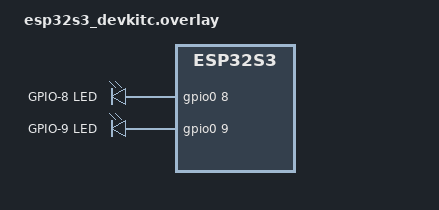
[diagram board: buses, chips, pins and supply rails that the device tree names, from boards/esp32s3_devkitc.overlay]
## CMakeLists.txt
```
cmake_minimum_required(VERSION 3.20.0)

find_package(Zephyr REQUIRED HINTS $ENV{ZEPHYR_BASE})
project(multi_thread_blinky LANGUAGES C)

target_sources(app PRIVATE src/main.c)
```

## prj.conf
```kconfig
# esp32s3_demo/prj.conf
CONFIG_ESPTOOLPY_FLASHSIZE_16MB=y
CONFIG_GPIO=y
CONFIG_LOG=y
CONFIG_LOG_DEFAULT_LEVEL=3
CONFIG_MAIN_STACK_SIZE=4096

# Use minimal C library to avoid picolibc/newlib complications
CONFIG_MINIMAL_LIBC=y
CONFIG_PICOLIBC=n
CONFIG_NEWLIB_LIBC=n

# Comms

CONFIG_CONSOLE=y
CONFIG_UART_CONSOLE=y
CONFIG_SERIAL=y
CONFIG_STDOUT_CONSOLE=y

# For debug
CONFIG_DEBUG=y
CONFIG_DEBUG_THREAD_INFO=y
CONFIG_ASSERT=y

# Thread Analyzer (diagnostic - off by default). Uncomment all three to print
# per-thread stack high-water marks to the console every 10 s; useful for
# checking stack headroom or right-sizing stacks. THREAD_ANALYZER auto-selects
# INIT_STACKS so the figures are accurate. Leave commented for normal runs.
# CONFIG_THREAD_ANALYZER=y
# CONFIG_THREAD_ANALYZER_AUTO=y
# CONFIG_THREAD_ANALYZER_AUTO_INTERVAL=10
```

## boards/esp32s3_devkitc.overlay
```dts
/ {
    aliases {
        led0 = &onboard_led;
        led1 = &second_led;
    };

    leds {
        compatible = "gpio-leds";

        onboard_led: led_0 {
            gpios = <&gpio0 8 GPIO_ACTIVE_HIGH>;
            label = "GPIO-8 LED";
        };

        second_led: led_1 {
            gpios = <&gpio0 9 GPIO_ACTIVE_HIGH>;
            label = "GPIO-9 LED";
        };
    };
};

&flash0 {
	reg = <0x0 DT_SIZE_M(16)>;
};
```

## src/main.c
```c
/*
 * Copyright (c) 2025 John O'Sullivan
 *
 * SPDX-License-Identifier: Apache-2.0
 */

#include <zephyr/kernel.h>
#include <zephyr/drivers/gpio.h>
#include <zephyr/logging/log.h>

LOG_MODULE_REGISTER(mtblink, LOG_LEVEL_INF);

/* Two LED bindings pulled from the overlay aliases. */
static const struct gpio_dt_spec led0 = GPIO_DT_SPEC_GET(DT_ALIAS(led0), gpios);
static const struct gpio_dt_spec led1 = GPIO_DT_SPEC_GET(DT_ALIAS(led1), gpios);

struct blink_ctx {
    const struct gpio_dt_spec *led;
    uint32_t interval_ms;
    const char *name;
};

/*
 * Thread stacks and priorities (lower number = higher priority).
 *
 * 2048 bytes per thread, not 1024: each blink thread calls LOG_INF() every
 * iteration, and on Xtensa (ESP32-S3) register-window spills plus the logging
 * format path could push stack usage past 1 KB. A 1 KB stack may overflow here - the
 * classic "LED blinks once, then the thread faults" symptom. Stack usage also
 * varies with the Zephyr SDK / GCC version, so leave generous headroom.
 */
K_THREAD_STACK_DEFINE(led0_stack, 2048);
K_THREAD_STACK_DEFINE(led1_stack, 2048);
static struct k_thread led0_thread;
static struct k_thread led1_thread;

static void blink_thread(void *p1, void *p2, void *p3)
{
    ARG_UNUSED(p2);
    ARG_UNUSED(p3);

    struct blink_ctx *ctx = p1;
    bool state = false;

    while (1) {
        gpio_pin_set_dt(ctx->led, state);
        LOG_INF("%s toggled %s", ctx->name, state ? "ON" : "OFF");
        state = !state;
        k_msleep(ctx->interval_ms);
    }
}

static int setup_led(const struct gpio_dt_spec *led)
{
    if (!device_is_ready(led->port)) {
        LOG_ERR("LED port not ready");
        return -ENODEV;
    }
    return gpio_pin_configure_dt(led, GPIO_OUTPUT_INACTIVE);
}

int main(void)
{
    if (setup_led(&led0) < 0 || setup_led(&led1) < 0) {
        return 0;
    }

    /*
     * These contexts must outlive main(): the blink threads keep dereferencing
     * &ctx0/&ctx1 after main() returns, so they need static (not automatic)
     * storage duration. Dropping `static` here would leave dangling pointers.
     */
    static struct blink_ctx ctx0 = {
        .led = &led0,
        .interval_ms = 300,
        .name = "LED0",
    };
    static struct blink_ctx ctx1 = {
        .led = &led1,
        .interval_ms = 700,
        .name = "LED1",
    };

    k_thread_create(&led0_thread, led0_stack, K_THREAD_STACK_SIZEOF(led0_stack),
                    blink_thread, &ctx0, NULL, NULL,
                    K_PRIO_PREEMPT(7), 0, K_NO_WAIT);
    k_thread_name_set(&led0_thread, "led0_blink");

    k_thread_create(&led1_thread, led1_stack, K_THREAD_STACK_SIZEOF(led1_stack),
                    blink_thread, &ctx1, NULL, NULL,
                    K_PRIO_PREEMPT(8), 0, K_NO_WAIT);
    k_thread_name_set(&led1_thread, "led1_blink");

    LOG_INF("Multi-thread blinky started (LED0=%u ms, LED1=%u ms)",
            ctx0.interval_ms, ctx1.interval_ms);

    return 0;
}
```
